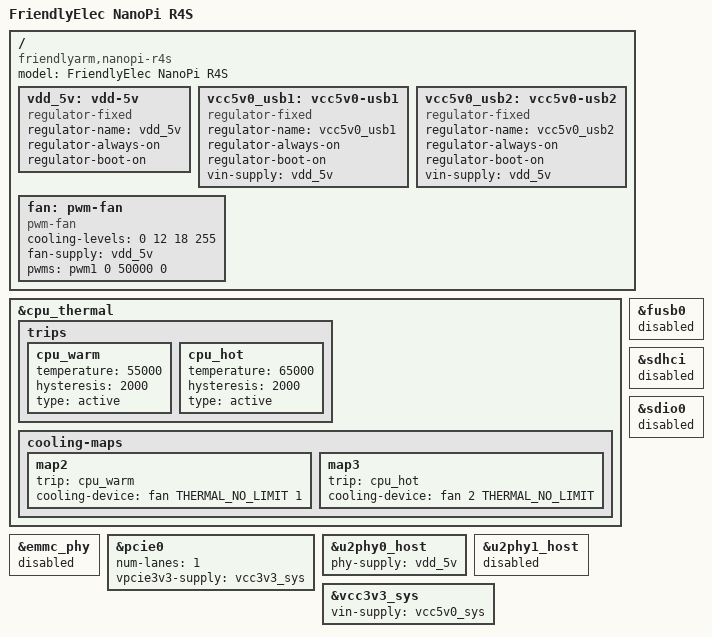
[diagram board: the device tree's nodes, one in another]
// SPDX-License-Identifier: (GPL-2.0+ OR MIT)
/*
 * FriendlyElec NanoPi R4S board device tree source
 *
 * Copyright (c) 2020 FriendlyElec Computer Tech. Co., Ltd.
 * (http://www.friendlyarm.com)
 *
 * Copyright (c) 2018 Collabora Ltd.
 * Copyright (c) 2019 Arm Ltd.
 */

/dts-v1/;
#include "rk3399-nanopi4.dtsi"

/ {
	model = "FriendlyElec NanoPi R4S";
	compatible = "friendlyarm,nanopi-r4s", "rockchip,rk3399";

	vdd_5v: vdd-5v {
		compatible = "regulator-fixed";
		regulator-name = "vdd_5v";
		regulator-always-on;
		regulator-boot-on;
	};

	vcc5v0_usb1: vcc5v0-usb1 {
		compatible = "regulator-fixed";
		regulator-name = "vcc5v0_usb1";
		regulator-always-on;
		regulator-boot-on;
		vin-supply = <&vdd_5v>;
	};

	vcc5v0_usb2: vcc5v0-usb2 {
		compatible = "regulator-fixed";
		regulator-name = "vcc5v0_usb2";
		regulator-always-on;
		regulator-boot-on;
		vin-supply = <&vdd_5v>;
	};

	fan: pwm-fan {
		compatible = "pwm-fan";
		/*
		 * With 20KHz PWM and an EVERCOOL EC4007H12SA fan, these levels
		 * work out to 0, ~1200, ~3000, and 5000RPM respectively.
		 */
		cooling-levels = <0 12 18 255>;
		#cooling-cells = <2>;
		fan-supply = <&vdd_5v>;
		pwms = <&pwm1 0 50000 0>;
	};
};

&cpu_thermal {
	trips {
		cpu_warm: cpu_warm {
			temperature = <55000>;
			hysteresis = <2000>;
			type = "active";
		};

		cpu_hot: cpu_hot {
			temperature = <65000>;
			hysteresis = <2000>;
			type = "active";
		};
	};

	cooling-maps {
		map2 {
			trip = <&cpu_warm>;
			cooling-device = <&fan THERMAL_NO_LIMIT 1>;
		};

		map3 {
			trip = <&cpu_hot>;
			cooling-device = <&fan 2 THERMAL_NO_LIMIT>;
		};
	};
};

&emmc_phy {
	status = "disabled";
};

&fusb0 {
	status = "disabled";
};

&pcie0 {
	num-lanes = <1>;
	vpcie3v3-supply = <&vcc3v3_sys>;
};

&sdhci {
	status = "disabled";
};

&sdio0 {
	status = "disabled";
};

&u2phy0_host {
	phy-supply = <&vdd_5v>;
};

&u2phy1_host {
	status = "disabled";
};

&vcc3v3_sys {
	vin-supply = <&vcc5v0_sys>;
};
